# StarFive VisionFive 2 v1.2A register map
File version: 0.1
Registers are 32-bit, read-write, reset 0x0 unless marked. A register's access mark holds for its fields unless they carry their own. Offsets are from the block's base; [hi:lo] are bit positions; {n}, {i} and the like mark numbered series; 'fields as' and 'values as' point back to an identical list.

## pmu — From starfive,jh7110-pmu, peripheral generator
Base 0x17030000
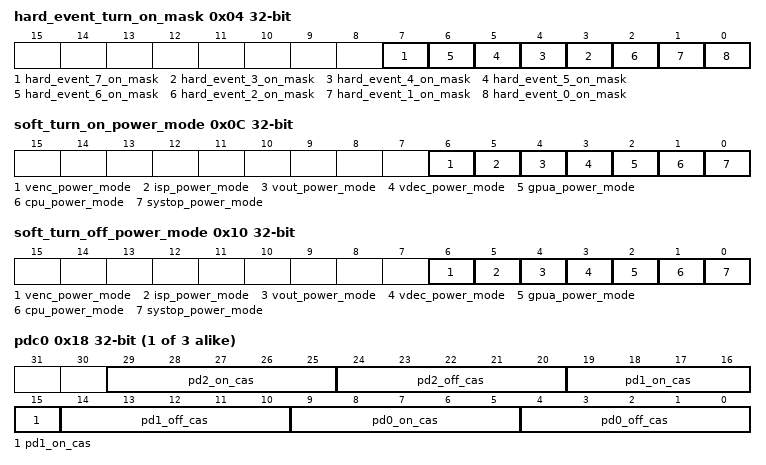
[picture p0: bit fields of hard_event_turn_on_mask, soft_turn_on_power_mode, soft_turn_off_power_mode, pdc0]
0x04 hard_event_turn_on_mask — Hardware Event Turn-On Mask
  [7] hard_event_7_on_mask — GPU event, 1: mask hardware event, 0: enable hardware event
  [n] hard_event_{n}_on_mask (n=3..6) — RGPIO{n-3} event encourage turn-on sequence, 1: mask hardware event, 0: enable hardware event
  [2] hard_event_2_on_mask — RFU, 1: mask hardware event, 0: enable hardware event
  [1] hard_event_1_on_mask — GMAC event encourage turn-on sequence, 1: mask hardware event, 0: enable hardware event
  [0] hard_event_0_on_mask — RTC event encourage turn-on sequence, 1: mask hardware event, 0: enable hardware event
0x0C soft_turn_on_power_mode — Software Turn-On Power Mode
  [6] venc_power_mode — VENC turn-on power mode.
  [5] isp_power_mode — ISP turn-on power mode.
  [4] vout_power_mode — VOUT turn-on power mode.
  [3] vdec_power_mode — VDEC turn-on power mode.
  [2] gpua_power_mode — GPUA turn-on power mode.
  [1] cpu_power_mode — CPU turn-on power mode.
  [0] systop_power_mode — SYSTOP turn-on power mode.
0x10 soft_turn_off_power_mode — Software Turn-Off Power Mode
  [6] venc_power_mode — VENC turn-off power mode.
  [5] isp_power_mode — ISP turn-off power mode.
  [4] vout_power_mode — VOUT turn-off power mode.
  [3] vdec_power_mode — VDEC turn-off power mode.
  [2] gpua_power_mode — GPUA turn-off power mode.
  [1] cpu_power_mode — CPU turn-off power mode.
  [0] systop_power_mode — SYSTOP turn-off power mode.
0x14 timeout_seq_thd — Threshold Sequence Timeout
  [15:0] timeout_seq_thd
{0x18+4i} pdc{i} (i=0..2) — Powerdomain Cascade {i}
  [29:25] pd{3i+2}_on_cas — Power domain {3i+2} turn-on cascade. The register value indicates the power-on sequence of this domain. 0 means the highest priority. System only accepts value from 0 to 7, any other value is invalid.
  [24:20] pd{3i+2}_off_cas — Power domain {3i+2} turn-off cascade. The register value indicates the power-off sequence of this domain. 0 means the highest priority. System only accepts value from 0 to 7, any other value is invalid.
  [19:15] pd{3i+1}_on_cas — Power domain {3i+1} turn-on cascade. The register value indicates the power-on sequence of this domain. 0 means the highest priority. System only accepts value from 0 to 7, any other value is invalid.
  [14:10] pd{3i+1}_off_cas — Power domain {3i+1} turn-off cascade. The register value indicates the power-off sequence of this domain. 0 means the highest priority. System only accepts value from 0 to 7, any other value is invalid.
  [9:5] pd{3i}_on_cas — Power domain {3i} turn-on cascade. The register value indicates the power-on sequence of this domain. 0 means the highest priority. System only accepts value from 0 to 7, any other value is invalid.
  [4:0] pd{3i}_off_cas — Power domain {3i} turn-off cascade. The register value indicates the power-off sequence of this domain. 0 means the highest priority. System only accepts value from 0 to 7, any other value is invalid.
0x44 sw_encourage — Software Encouragement
  [7:0] sw_encourage
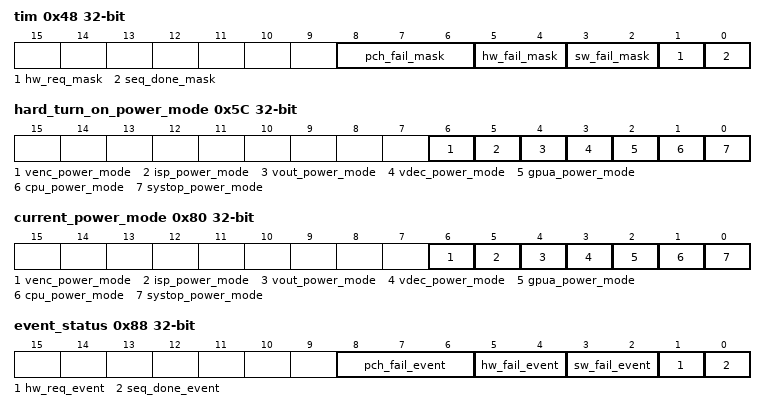
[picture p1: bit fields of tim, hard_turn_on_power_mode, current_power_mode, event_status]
0x48 tim — TIMER Interrupt Mask
  [8:6] pch_fail_mask — Mask the P-channel encouragement failure event. 0: mask, 1: unmask
  [5:4] hw_fail_mask — Mask the hardware encouragement failure event. 0: mask, 1: unmask
  [3:2] sw_fail_mask — Mask the software encouragement failure event. 0: mask, 1: unmask
  [1] hw_req_mask — Mask the hardware encouragement request. 0: mask, 1: unmask
  [0] seq_done_mask — Mask the sequence complete event. 0: mask, 1: unmask
0x4C pch_bypass — P-channel Bypass
  [0] pch_bypass — Bypass P-channel. 0: enable p-channel, 1: bypass p-channel
0x50 pch_pstate — P-channel PSTATE
  [4:0] pch_pstate — P-channel state set
0x54 pch_timeout — P-channel Timeout Threshold
  [7:0] pch_timeout — P-channel waiting device acknowledge timeout.
0x58 lp_timeout — LP Cell Control Timeout Threshold
  [7:0] lp_timeout — LP Cell Control signal waiting carries acknowledge timeout.
0x5C hard_turn_on_power_mode — Hardware Turn-On Power Mode
  fields as soft_turn_on_power_mode
0x80 current_power_mode
  fields as soft_turn_on_power_mode
0x84 current_seq_state — Current Sequence State
  [1:0] power_mode_cur ro — Current sequence state.
0x88 event_status — PMU Event Status
  [8:6] pch_fail_event ro — P-channel failure.
  [5:4] hw_fail_event ro — Hardware encouragement failure.
  [3:2] sw_fail_event ro — Software encouragement failure.
  [1] hw_req_event ro — Hardware encouragement request.
  [0] seq_done_event ro — Sequence complete.
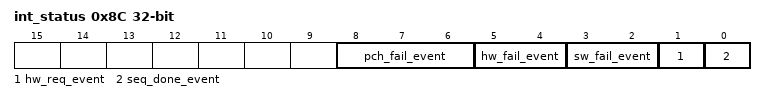
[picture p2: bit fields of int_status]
0x8C int_status — PMU Interrupt Status
  fields as event_status
0x90 hw_event_crd — Hardware Event Record
  [7:0] hw_event_crd ro — Hardware Event Record.
0x94 encourage_type_crd — Hardware Event Type Record
  [0] encourage_type_crd ro — Hardware/Software encouragement type record. 0: Software, 1: Hardware.
0x98 pch_active — P-channel PACTIVE Status
  [10:0] pch_active ro — P-channel PACTIVE status.
